# PIC32MZ2048EFM144 register map
Registers are 32-bit, access not given, reset 0x0 unless marked. A register's access mark holds for its fields unless they carry their own. Offsets are from the block's base; [hi:lo] are bit positions; {n}, {i} and the like mark numbered series.

## PORTC — PORTC peripheral
Base 0xBF860200
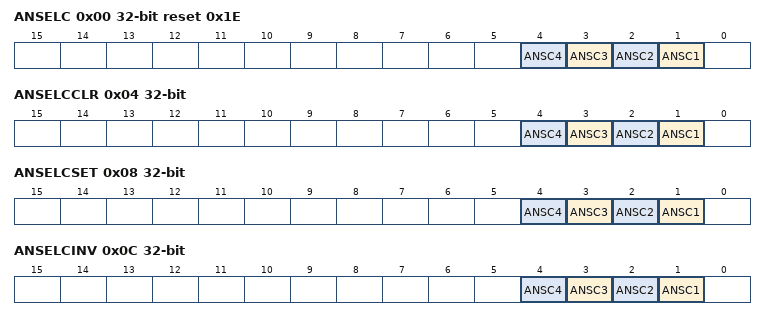
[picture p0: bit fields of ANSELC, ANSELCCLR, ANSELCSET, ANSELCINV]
0x00 ANSELC reset 0x1E
  [n] ANSC{n} (n=1..4)
0x04 ANSELCCLR
  [n] ANSC{n} (n=1..4)
0x08 ANSELCSET
  [n] ANSC{n} (n=1..4)
0x0C ANSELCINV
  [n] ANSC{n} (n=1..4)
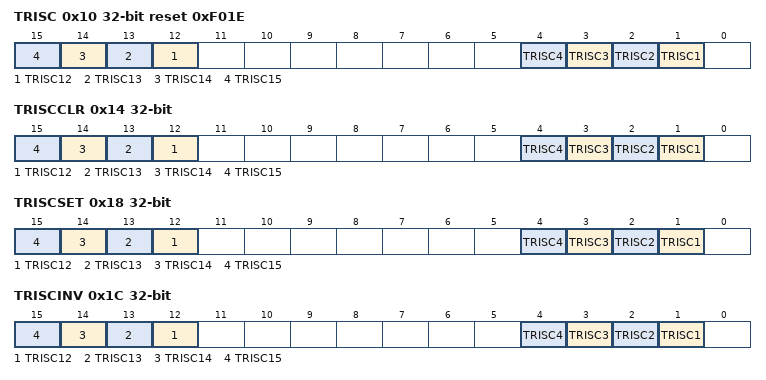
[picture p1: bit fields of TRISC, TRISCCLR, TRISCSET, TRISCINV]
0x10 TRISC reset 0xF01E
  [n] TRISC{n} (n=12..15), [n] TRISC{n} (n=1..4)
0x14 TRISCCLR
  [n] TRISC{n} (n=12..15), [n] TRISC{n} (n=1..4)
0x18 TRISCSET
  [n] TRISC{n} (n=12..15), [n] TRISC{n} (n=1..4)
0x1C TRISCINV
  [n] TRISC{n} (n=12..15), [n] TRISC{n} (n=1..4)
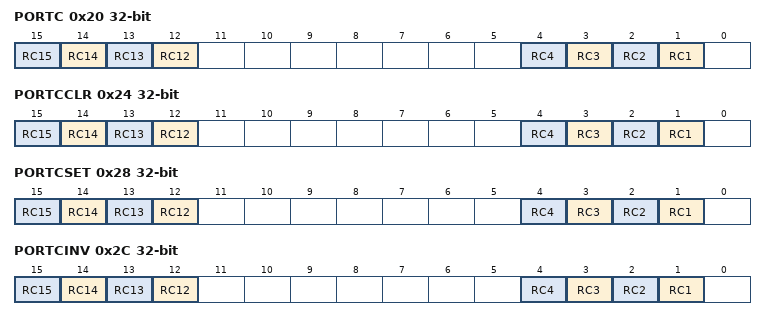
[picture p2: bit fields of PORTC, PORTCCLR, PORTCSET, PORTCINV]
0x20 PORTC
  [n] RC{n} (n=12..15), [n] RC{n} (n=1..4)
0x24 PORTCCLR
  [n] RC{n} (n=12..15), [n] RC{n} (n=1..4)
0x28 PORTCSET
  [n] RC{n} (n=12..15), [n] RC{n} (n=1..4)
0x2C PORTCINV
  [n] RC{n} (n=12..15), [n] RC{n} (n=1..4)
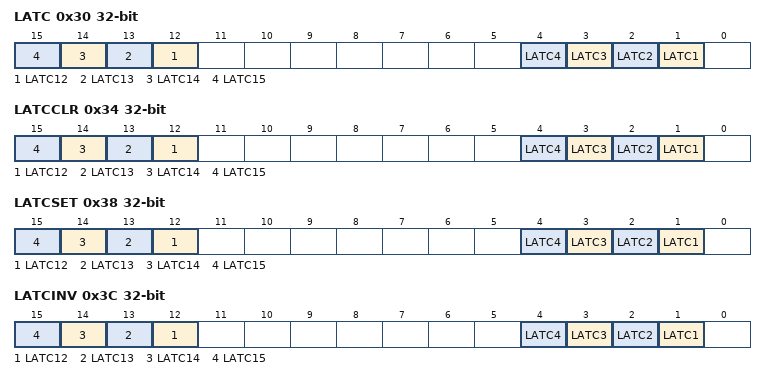
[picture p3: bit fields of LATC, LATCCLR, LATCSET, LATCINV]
0x30 LATC
  [n] LATC{n} (n=12..15), [n] LATC{n} (n=1..4)
0x34 LATCCLR
  [n] LATC{n} (n=12..15), [n] LATC{n} (n=1..4)
0x38 LATCSET
  [n] LATC{n} (n=12..15), [n] LATC{n} (n=1..4)
0x3C LATCINV
  [n] LATC{n} (n=12..15), [n] LATC{n} (n=1..4)
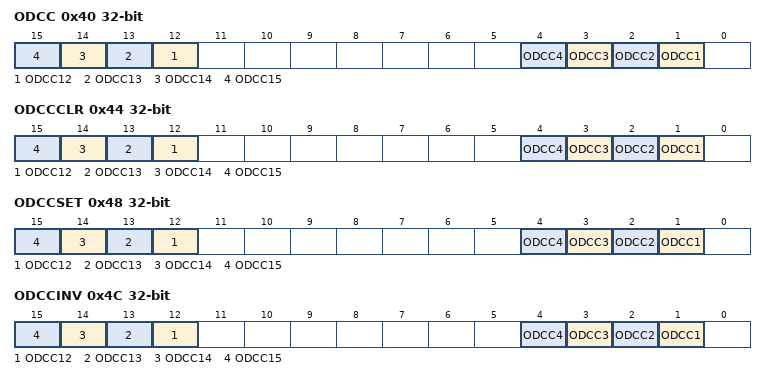
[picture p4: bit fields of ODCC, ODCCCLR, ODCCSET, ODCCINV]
0x40 ODCC
  [n] ODCC{n} (n=12..15), [n] ODCC{n} (n=1..4)
0x44 ODCCCLR
  [n] ODCC{n} (n=12..15), [n] ODCC{n} (n=1..4)
0x48 ODCCSET
  [n] ODCC{n} (n=12..15), [n] ODCC{n} (n=1..4)
0x4C ODCCINV
  [n] ODCC{n} (n=12..15), [n] ODCC{n} (n=1..4)
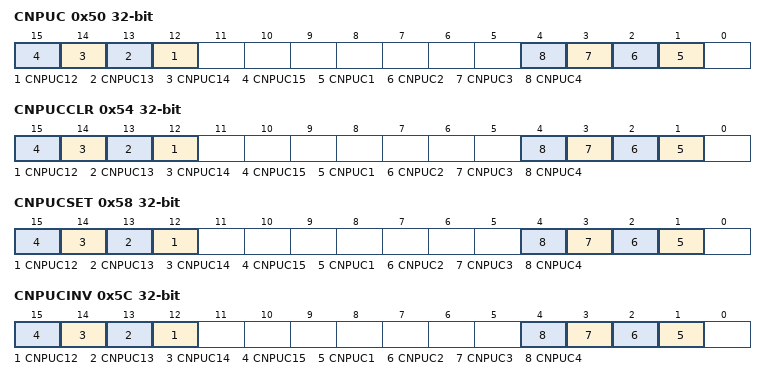
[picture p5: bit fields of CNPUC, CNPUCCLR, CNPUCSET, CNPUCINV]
0x50 CNPUC
  [n] CNPUC{n} (n=12..15), [n] CNPUC{n} (n=1..4)
0x54 CNPUCCLR
  [n] CNPUC{n} (n=12..15), [n] CNPUC{n} (n=1..4)
0x58 CNPUCSET
  [n] CNPUC{n} (n=12..15), [n] CNPUC{n} (n=1..4)
0x5C CNPUCINV
  [n] CNPUC{n} (n=12..15), [n] CNPUC{n} (n=1..4)
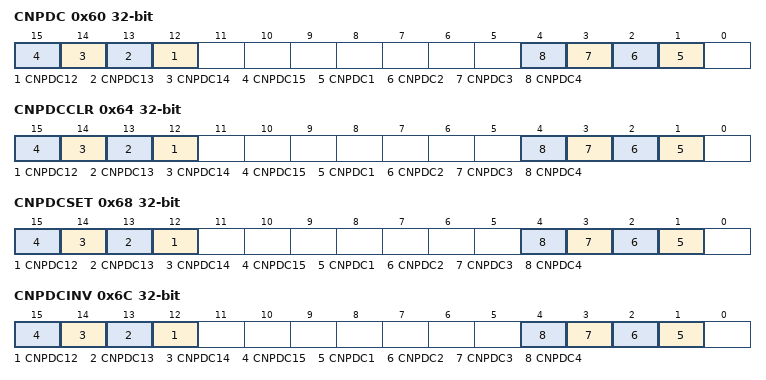
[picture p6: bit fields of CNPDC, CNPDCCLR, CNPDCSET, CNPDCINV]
0x60 CNPDC
  [n] CNPDC{n} (n=12..15), [n] CNPDC{n} (n=1..4)
0x64 CNPDCCLR
  [n] CNPDC{n} (n=12..15), [n] CNPDC{n} (n=1..4)
0x68 CNPDCSET
  [n] CNPDC{n} (n=12..15), [n] CNPDC{n} (n=1..4)
0x6C CNPDCINV
  [n] CNPDC{n} (n=12..15), [n] CNPDC{n} (n=1..4)
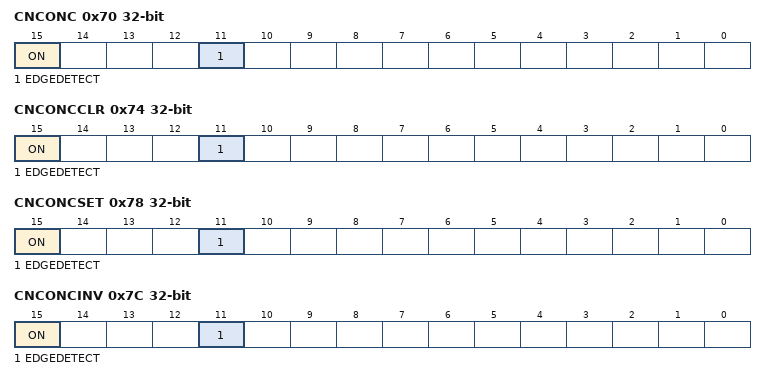
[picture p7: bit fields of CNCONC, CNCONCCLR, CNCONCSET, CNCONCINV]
0x70 CNCONC
  [15] ON, [11] EDGEDETECT
0x74 CNCONCCLR
  [15] ON, [11] EDGEDETECT
0x78 CNCONCSET
  [15] ON, [11] EDGEDETECT
0x7C CNCONCINV
  [15] ON, [11] EDGEDETECT
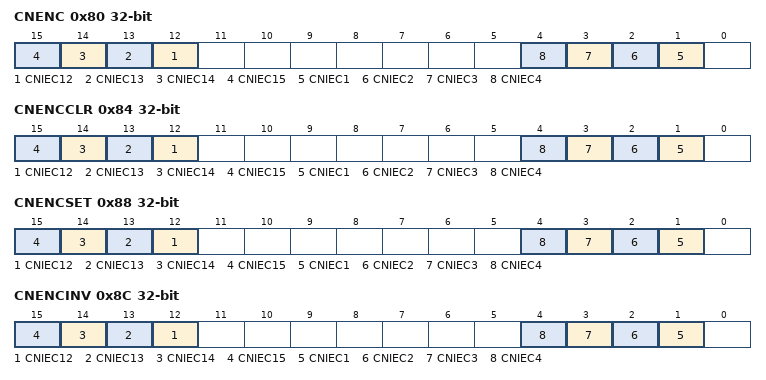
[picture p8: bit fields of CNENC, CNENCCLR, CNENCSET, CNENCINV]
0x80 CNENC
  [n] CNIEC{n} (n=12..15), [n] CNIEC{n} (n=1..4)
0x84 CNENCCLR
  [n] CNIEC{n} (n=12..15), [n] CNIEC{n} (n=1..4)
0x88 CNENCSET
  [n] CNIEC{n} (n=12..15), [n] CNIEC{n} (n=1..4)
0x8C CNENCINV
  [n] CNIEC{n} (n=12..15), [n] CNIEC{n} (n=1..4)
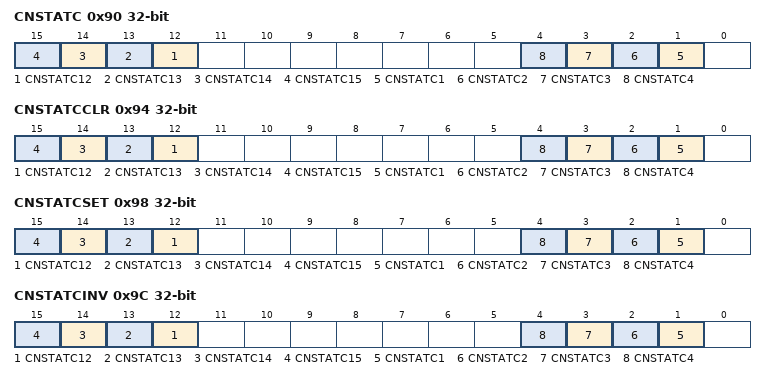
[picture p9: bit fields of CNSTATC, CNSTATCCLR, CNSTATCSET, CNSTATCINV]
0x90 CNSTATC
  [n] CNSTATC{n} (n=12..15), [n] CNSTATC{n} (n=1..4)
0x94 CNSTATCCLR
  [n] CNSTATC{n} (n=12..15), [n] CNSTATC{n} (n=1..4)
0x98 CNSTATCSET
  [n] CNSTATC{n} (n=12..15), [n] CNSTATC{n} (n=1..4)
0x9C CNSTATCINV
  [n] CNSTATC{n} (n=12..15), [n] CNSTATC{n} (n=1..4)
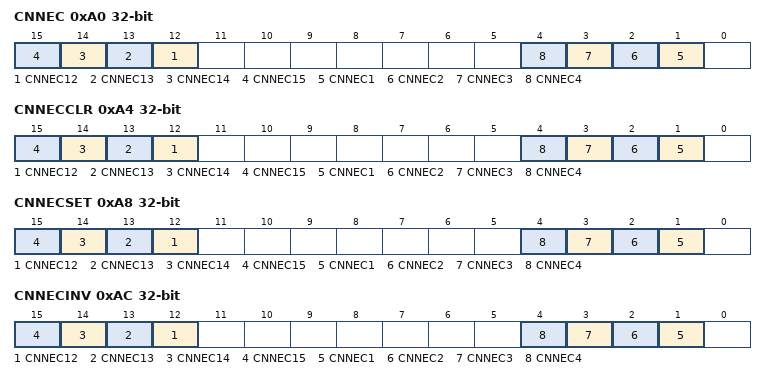
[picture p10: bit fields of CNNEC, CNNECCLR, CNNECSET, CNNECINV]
0xA0 CNNEC
  [n] CNNEC{n} (n=12..15), [n] CNNEC{n} (n=1..4)
0xA4 CNNECCLR
  [n] CNNEC{n} (n=12..15), [n] CNNEC{n} (n=1..4)
0xA8 CNNECSET
  [n] CNNEC{n} (n=12..15), [n] CNNEC{n} (n=1..4)
0xAC CNNECINV
  [n] CNNEC{n} (n=12..15), [n] CNNEC{n} (n=1..4)
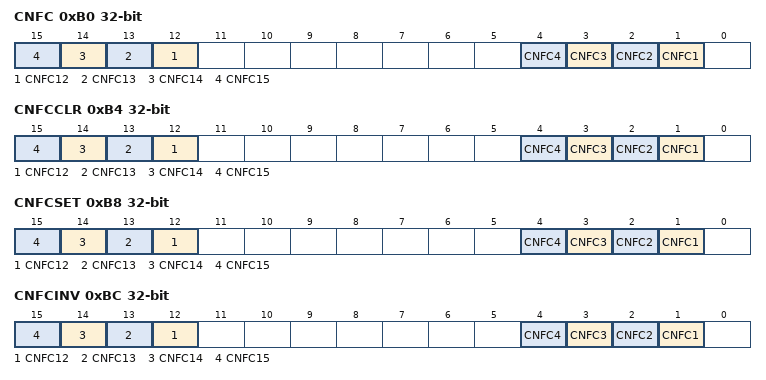
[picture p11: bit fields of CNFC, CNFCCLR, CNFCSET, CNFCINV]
0xB0 CNFC
  [n] CNFC{n} (n=12..15), [n] CNFC{n} (n=1..4)
0xB4 CNFCCLR
  [n] CNFC{n} (n=12..15), [n] CNFC{n} (n=1..4)
0xB8 CNFCSET
  [n] CNFC{n} (n=12..15), [n] CNFC{n} (n=1..4)
0xBC CNFCINV
  [n] CNFC{n} (n=12..15), [n] CNFC{n} (n=1..4)

## PORTD — PORTD peripheral
Base 0xBF860300
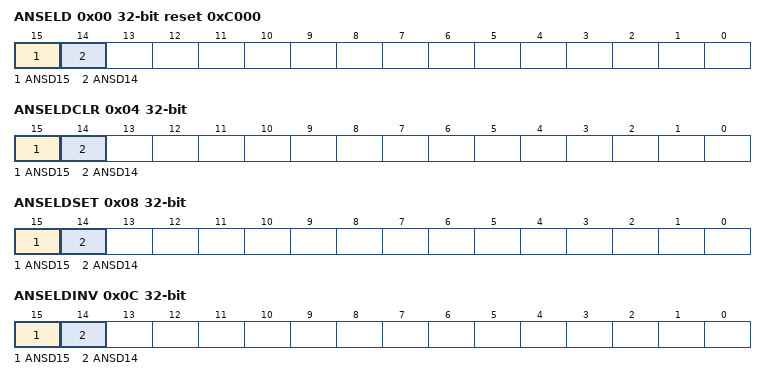
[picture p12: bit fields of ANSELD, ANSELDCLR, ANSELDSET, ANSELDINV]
0x00 ANSELD reset 0xC000
  [15] ANSD15, [14] ANSD14
0x04 ANSELDCLR
  [15] ANSD15, [14] ANSD14
0x08 ANSELDSET
  [15] ANSD15, [14] ANSD14
0x0C ANSELDINV
  [15] ANSD15, [14] ANSD14
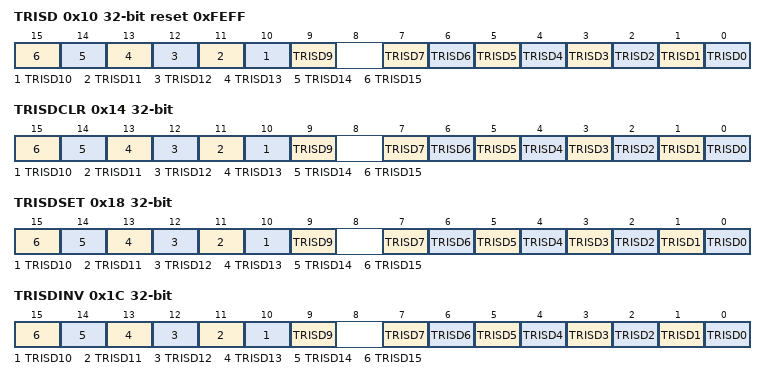
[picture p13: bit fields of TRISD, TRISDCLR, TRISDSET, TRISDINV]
0x10 TRISD reset 0xFEFF
  [n] TRISD{n} (n=9..15), [n] TRISD{n} (n=0..7)
0x14 TRISDCLR
  [n] TRISD{n} (n=9..15), [n] TRISD{n} (n=0..7)
0x18 TRISDSET
  [n] TRISD{n} (n=9..15), [n] TRISD{n} (n=0..7)
0x1C TRISDINV
  [n] TRISD{n} (n=9..15), [n] TRISD{n} (n=0..7)
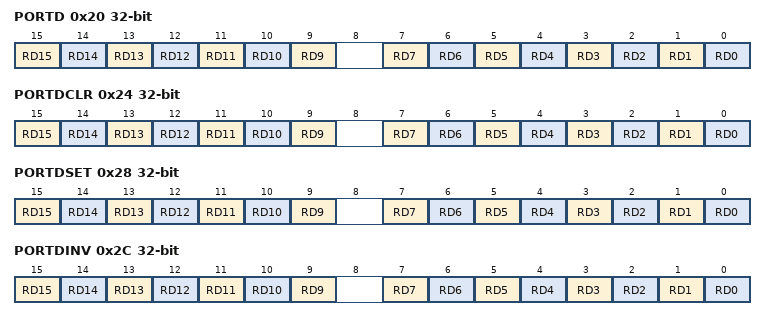
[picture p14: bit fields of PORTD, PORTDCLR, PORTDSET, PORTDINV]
0x20 PORTD
  [n] RD{n} (n=9..15), [n] RD{n} (n=0..7)
0x24 PORTDCLR
  [n] RD{n} (n=9..15), [n] RD{n} (n=0..7)
0x28 PORTDSET
  [n] RD{n} (n=9..15), [n] RD{n} (n=0..7)
0x2C PORTDINV
  [n] RD{n} (n=9..15), [n] RD{n} (n=0..7)
0x30 LATD
  [n] LATD{n} (n=9..15), [n] LATD{n} (n=0..7)
0x34 LATDCLR
  [n] LATD{n} (n=9..15), [n] LATD{n} (n=0..7)
0x38 LATDSET
  [n] LATD{n} (n=9..15), [n] LATD{n} (n=0..7)
0x3C LATDINV
  [n] LATD{n} (n=9..15), [n] LATD{n} (n=0..7)
0x40 ODCD
  [n] ODCD{n} (n=9..15), [n] ODCD{n} (n=0..7)
0x44 ODCDCLR
  [n] ODCD{n} (n=9..15), [n] ODCD{n} (n=0..7)
0x48 ODCDSET
  [n] ODCD{n} (n=9..15), [n] ODCD{n} (n=0..7)
0x4C ODCDINV
  [n] ODCD{n} (n=9..15), [n] ODCD{n} (n=0..7)
0x50 CNPUD
  [n] CNPUD{n} (n=9..15), [n] CNPUD{n} (n=0..7)
0x54 CNPUDCLR
  [n] CNPUD{n} (n=9..15), [n] CNPUD{n} (n=0..7)
0x58 CNPUDSET
  [n] CNPUD{n} (n=9..15), [n] CNPUD{n} (n=0..7)
0x5C CNPUDINV
  [n] CNPUD{n} (n=9..15), [n] CNPUD{n} (n=0..7)
0x60 CNPDD
  [n] CNPDD{n} (n=9..15), [n] CNPDD{n} (n=0..7)
0x64 CNPDDCLR
  [n] CNPDD{n} (n=9..15), [n] CNPDD{n} (n=0..7)
0x68 CNPDDSET
  [n] CNPDD{n} (n=9..15), [n] CNPDD{n} (n=0..7)
0x6C CNPDDINV
  [n] CNPDD{n} (n=9..15), [n] CNPDD{n} (n=0..7)
0x70 CNCOND
  [15] ON, [11] EDGEDETECT
0x74 CNCONDCLR
  [15] ON, [11] EDGEDETECT
0x78 CNCONDSET
  [15] ON, [11] EDGEDETECT
0x7C CNCONDINV
  [15] ON, [11] EDGEDETECT
0x80 CNEND
  [n] CNIED{n} (n=9..15), [n] CNIED{n} (n=0..7)
0x84 CNENDCLR
  [n] CNIED{n} (n=9..15), [n] CNIED{n} (n=0..7)
0x88 CNENDSET
  [n] CNIED{n} (n=9..15), [n] CNIED{n} (n=0..7)
0x8C CNENDINV
  [n] CNIED{n} (n=9..15), [n] CNIED{n} (n=0..7)
0x90 CNSTATD
  [n] CNSTATD{n} (n=9..15), [n] CNSTATD{n} (n=0..7)
0x94 CNSTATDCLR
  [n] CNSTATD{n} (n=9..15), [n] CNSTATD{n} (n=0..7)
0x98 CNSTATDSET
  [n] CNSTATD{n} (n=9..15), [n] CNSTATD{n} (n=0..7)
0x9C CNSTATDINV
  [n] CNSTATD{n} (n=9..15), [n] CNSTATD{n} (n=0..7)
0xA0 CNNED
  [n] CNNED{n} (n=9..15), [n] CNNED{n} (n=0..7)
0xA4 CNNEDCLR
  [n] CNNED{n} (n=9..15), [n] CNNED{n} (n=0..7)
0xA8 CNNEDSET
  [n] CNNED{n} (n=9..15), [n] CNNED{n} (n=0..7)
0xAC CNNEDINV
  [n] CNNED{n} (n=9..15), [n] CNNED{n} (n=0..7)
0xB0 CNFD
  [n] CNFD{n} (n=9..15), [n] CNFD{n} (n=0..7)
0xB4 CNFDCLR
  [n] CNFD{n} (n=9..15), [n] CNFD{n} (n=0..7)
0xB8 CNFDSET
  [n] CNFD{n} (n=9..15), [n] CNFD{n} (n=0..7)
0xBC CNFDINV
  [n] CNFD{n} (n=9..15), [n] CNFD{n} (n=0..7)
